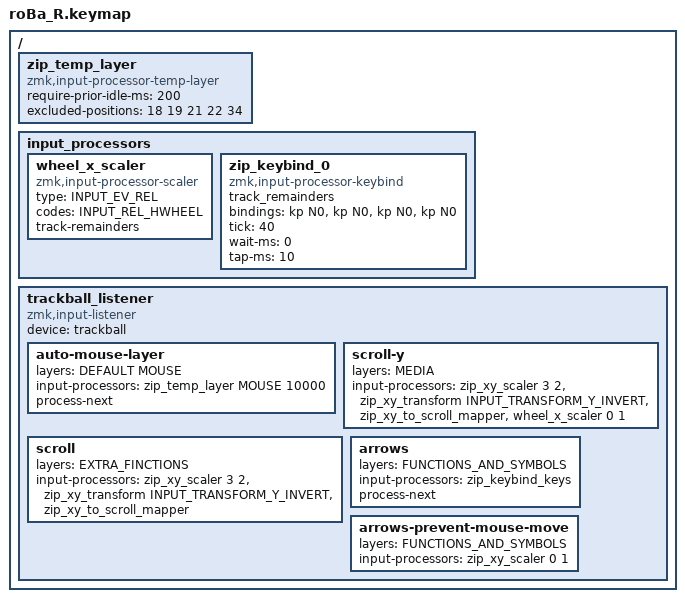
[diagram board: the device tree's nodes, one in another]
#include "roBa_L.keymap"

#include <input/processors.dtsi>
#include <dt-bindings/zmk/input_transform.h>
#include <zephyr/dt-bindings/input/input-event-codes.h>
#include <input/processors/zmk-input-processor-keybind.dtsi>

/ {
    /omit-if-no-ref/ zip_temp_layer: zip_temp_layer {
        compatible = "zmk,input-processor-temp-layer";
        #input-processor-cells = <2>;
        require-prior-idle-ms = <200>;
        excluded-positions = <
            18 // J
            19 // K
            // 20 // L
            21 // ;
            22 // Z
            // 31 // .
            // 32 // ,
            // 33 // /
            34 // Ctrl
        >;
    };

    input_processors {
        wheel_x_scaler: wheel_x_scaler {
            compatible = "zmk,input-processor-scaler";
            #input-processor-cells = <2>;
            type = <INPUT_EV_REL>;
            codes = <INPUT_REL_HWHEEL>;
            track-remainders;
        };

        zip_keybind_0: zip_keybind_0 {
            compatible = "zmk,input-processor-keybind";
            #input-processor-cells = <0>;
            track_remainders;
            bindings = <
                &kp N0
                &kp N0
                &kp N0
                &kp N0
            >;
            tick = <40>;
            wait-ms = <0>;
            tap-ms = <10>;
            // mode = <1>
            // threshold = <10>
            // max_threshold = <200>
            // max_pending_activations = <10>
        };
    };

    trackball_listener {
        compatible = "zmk,input-listener";
        device = <&trackball>;

        auto-mouse-layer {
            layers = <DEFAULT MOUSE>;
            input-processors = <&zip_temp_layer MOUSE 10000>;
            process-next;
        };

        scroll-y {
            layers = <MEDIA>;
            input-processors =
                <&zip_xy_scaler 3 2>,
                <&zip_xy_transform INPUT_TRANSFORM_Y_INVERT>,
                <&zip_xy_to_scroll_mapper>,
                <&wheel_x_scaler 0 1>;
        };

        scroll {
            layers = <EXTRA_FINCTIONS>;
            input-processors =
                <&zip_xy_scaler 3 2>,
                <&zip_xy_transform INPUT_TRANSFORM_Y_INVERT>,
                <&zip_xy_to_scroll_mapper>;
        };

        arrows {
            layers = <FUNCTIONS_AND_SYMBOLS>;
            input-processors = <&zip_keybind_keys>;
            process-next;
        };

        arrows-prevent-mouse-move {
            layers = <FUNCTIONS_AND_SYMBOLS>;
            input-processors = <&zip_xy_scaler 0 1>;
        };

        // layer0 {
        //     layers = <0>;
        //     input-processors = <&zip_keybind_0>;
        //     process-next;
        // };

        // layer0-prevent-mouse-move {
        //     layers = <0>;
        //     input-processors = <&zip_xy_scaler 0 1>;
        // };
    };
};
